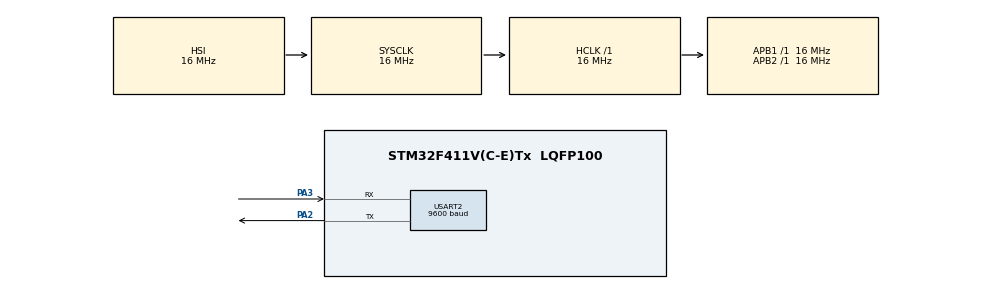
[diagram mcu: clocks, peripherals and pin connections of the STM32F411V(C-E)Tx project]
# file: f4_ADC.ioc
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Mcu.Family=STM32F4
Mcu.Name=STM32F411V(C-E)Tx
Mcu.Package=LQFP100
NVIC.PriorityGroup=NVIC_PRIORITYGROUP_4
PA2.Mode=Asynchronous
PA2.Signal=USART2_TX
PA3.Mode=Asynchronous
PA3.Signal=USART2_RX
ProjectManager.HeapSize=0x200
ProjectManager.StackSize=0x400
ProjectManager.TargetToolchain=STM32CubeIDE
RCC.AHBFreq_Value=16000000
RCC.APB1Freq_Value=16000000
RCC.APB2Freq_Value=16000000
RCC.CortexFreq_Value=16000000
RCC.HSE_VALUE=25000000
RCC.HSI_VALUE=16000000
RCC.LSE_VALUE=32768
RCC.SYSCLKFreq_VALUE=16000000
RCC.VCOOutputFreq_Value=192000000
USART2.BaudRate=9600
USART2.VirtualMode=VM_ASYNC
board=custom

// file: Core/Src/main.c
/* USER CODE BEGIN Header */
/**
  ******************************************************************************
  * @file           : main.c
  * @brief          : Main program body
  ******************************************************************************
  * @attention
  *
  * Copyright (c) 2023 STMicroelectronics.
  * All rights reserved.
  *
  * This software is licensed under terms that can be found in the LICENSE file
  * in the root directory of this software component.
  * If no LICENSE file comes with this software, it is provided AS-IS.
  *
  ******************************************************************************
  */
/* USER CODE END Header */
#include "main.h"

/* USER CODE BEGIN Includes */
#include <string.h>
#include <stdio.h>
#include <stdlib.h>
#include "stm32f4xx.h"
#include "stm32f4xx_hal.h"
/* USER CODE END Includes */

UART_HandleTypeDef huart2;

/* USER CODE BEGIN PV */
uint16_t adc_data;
char mode[6] = "MODE2";
char msg [20];
char msg2 [50];
volatile uint32_t counter = 0;
char systickStr[11];
/* USER CODE END PV */

void SystemClock_Config(void);
static void MX_GPIO_Init(void);
static void MX_USART2_UART_Init(void);

/* USER CODE BEGIN 0 */
void DelayMS(unsigned int time);
void SysTick_Init(uint32_t ticks);
int adc_check (void);
uint16_t adc_rx(void);
void adc_init(void);
void LED_init(void);
void Toggle_all_LEDs(void);
void printTimestamp(void);
void UART2_Init(void);
void UART_Tx(char c);
char UART_Rx(void);
uint16_t read_adc(uint8_t channel);
void Current_Measurement(void);
void Voltage_Measurement(void);
/* USER CODE END 0 */

int main(void)
{

  /* MCU Configuration--------------------------------------------------------*/

  /* Reset of all peripherals, Initializes the Flash interface and the Systick. */
  HAL_Init();

  /* Configure the system clock */
  SystemClock_Config();

  /* USER CODE BEGIN SysInit */
  SysTick_Init(16000);

  /* USER CODE END SysInit */

  /* Initialize all configured peripherals */
  MX_GPIO_Init();
  MX_USART2_UART_Init();
  /* USER CODE BEGIN 2 */
  LED_init();
  adc_init();
  /* USER CODE END 2 */

  /* Infinite loop */
  /* USER CODE BEGIN WHILE */
  while (1)
  {
	  Voltage_Measurement();
	  Current_Measurement();

	  DelayMS(500);
    /* USER CODE END WHILE */

  }
}

void SystemClock_Config(void)
{
  RCC_OscInitTypeDef RCC_OscInitStruct = {0};
  RCC_ClkInitTypeDef RCC_ClkInitStruct = {0};

  /** Configure the main internal regulator output voltage
  */
  __HAL_RCC_PWR_CLK_ENABLE();
  __HAL_PWR_VOLTAGESCALING_CONFIG(PWR_REGULATOR_VOLTAGE_SCALE1);

  /** Initializes the RCC Oscillators according to the specified parameters
  * in the RCC_OscInitTypeDef structure.
  */
  RCC_OscInitStruct.OscillatorType = RCC_OSCILLATORTYPE_HSI;
  RCC_OscInitStruct.HSIState = RCC_HSI_ON;
  RCC_OscInitStruct.HSICalibrationValue = RCC_HSICALIBRATION_DEFAULT;
  RCC_OscInitStruct.PLL.PLLState = RCC_PLL_NONE;
  if (HAL_RCC_OscConfig(&RCC_OscInitStruct) != HAL_OK)
  {
    Error_Handler();
  }

  /** Initializes the CPU, AHB and APB buses clocks
  */
  RCC_ClkInitStruct.ClockType = RCC_CLOCKTYPE_HCLK|RCC_CLOCKTYPE_SYSCLK
                              |RCC_CLOCKTYPE_PCLK1|RCC_CLOCKTYPE_PCLK2;
  RCC_ClkInitStruct.SYSCLKSource = RCC_SYSCLKSOURCE_HSI;
  RCC_ClkInitStruct.AHBCLKDivider = RCC_SYSCLK_DIV1;
  RCC_ClkInitStruct.APB1CLKDivider = RCC_HCLK_DIV1;
  RCC_ClkInitStruct.APB2CLKDivider = RCC_HCLK_DIV1;

  if (HAL_RCC_ClockConfig(&RCC_ClkInitStruct, FLASH_LATENCY_0) != HAL_OK)
  {
    Error_Handler();
  }
}

static void MX_USART2_UART_Init(void)
{

  huart2.Instance = USART2;
  huart2.Init.BaudRate = 9600;
  huart2.Init.WordLength = UART_WORDLENGTH_8B;
  huart2.Init.StopBits = UART_STOPBITS_1;
  huart2.Init.Parity = UART_PARITY_NONE;
  huart2.Init.Mode = UART_MODE_TX_RX;
  huart2.Init.HwFlowCtl = UART_HWCONTROL_NONE;
  huart2.Init.OverSampling = UART_OVERSAMPLING_16;
  if (HAL_UART_Init(&huart2) != HAL_OK)
  {
    Error_Handler();
  }

}

static void MX_GPIO_Init(void)
{

  /* GPIO Ports Clock Enable */
  __HAL_RCC_GPIOA_CLK_ENABLE();

}

/* USER CODE BEGIN 4 */

void Voltage_Measurement(void){
	  adc_data = read_adc(9);
	  // Voltage Measurement 30V
	  float Vin = (adc_data*(2.9)/4095.0);
//			  Vin = Vin*(30.0/2.72); //Correction for Voltage divider
	  Vin += (0.6/30.0)*Vin; //Correction using observation
	  sprintf(msg2, " Vol = %.3f V", Vin);
	  printTimestamp();
	  HAL_UART_Transmit(&huart2, (uint8_t*)(msg2), strlen(msg2), 200);
}

void Current_Measurement(void){

	adc_data = read_adc(8);
	// Current Measurement
	float Vin = (adc_data*(2.9)/4095.0);
	/*Divide Vin by the gain of the apmlifier in this line*/
	float Iin = Vin/(0.0008);
	sprintf(msg2, "Vol = %.3f V, I = %.3f A", Vin, Iin);
	printTimestamp();
	HAL_UART_Transmit(&huart2, (uint8_t*)(msg2), strlen(msg2), 200);
}

uint16_t adc_rx(void){

	uint16_t adcValue = 0;
	adcValue = ADC1->DR;

	return adcValue;
}

uint16_t read_adc(uint8_t channel) {
    // Set the channel in the sequence register
    ADC1->SQR3 = (channel & 0x1F);  // Assuming channel is less than 16

    // Start the conversion
    ADC1->CR2 |= ADC_CR2_SWSTART;  // Start conversion

    // Wait for the end of conversion
    while (!((ADC1->SR & ADC_SR_EOC) == ADC_SR_EOC)) {}

    // Read the converted value
    uint16_t result = ADC1->DR;

    return result;
}

int adc_check (void){
	int check = 0;
	if ((ADC1->SR & ADC_SR_EOC) == ADC_SR_EOC){
		check = 1;
	}
	return check;
}

void Toggle_all_LEDs(void){

	  GPIOD->ODR ^= 0x1000; // Green LED Toggle
	  GPIOD->ODR ^= 0x2000; // Orange LED Toggle
	  GPIOD->ODR ^= 0x4000; // Red LED Toggle
	  GPIOD->ODR ^= 0x8000; // Blue LED Toggle
}

void adc_init(void) {
    // Enable the ADC1 clock
    RCC->APB2ENR |= RCC_APB2ENR_ADC1EN;

    // Enable the GPIOB clock
    RCC->AHB1ENR |= RCC_AHB1ENR_GPIOBEN;

    // Configure PB1 as analog input
    GPIOB->MODER |= GPIO_MODER_MODER1; // Analog mode

    // Configure ADC settings
    ADC1->CR1 &= ~ADC_CR1_RES; // Clear the RES bits for 12-bit resolution
    ADC1->CR2 &= ~ADC_CR2_ALIGN; // Data right-aligned
    ADC1->CR2 |= ADC_CR2_CONT; // Continuous conversion mode
    ADC1->SQR3 &= ~ADC_SQR3_SQ1; // Clear the SQ1 bits
    ADC1->SQR3 |= 9 << ADC_SQR3_SQ1_Pos; // Set the channel number in SQ1 bits (Channel 9 for PB1)
    ADC1->SQR3 |= 8 << ADC_SQR3_SQ1_Pos; // Set the channel number in SQ1 bits (Channel 8 for PB0)
    // Enable the ADC
    ADC1->CR2 |= ADC_CR2_ADON;

    // Wait for ADC to be ready
    DelayMS(100);

    // Start the conversion
    ADC1->CR2 |= ADC_CR2_SWSTART;
}

void DelayMS(unsigned int time){

	for(int i=0; i<=time; i++){
		while ((SysTick->CTRL & 0x00010000) == 0){
				//Wait for 1 millisec.
		}
	}
}

void SysTick_Init(uint32_t ticks){

	SysTick->CTRL = 0; // Disable SysTick

	SysTick->LOAD = ticks-1; // Set Reload Register

	// Setting Interrupt Priority to the highest
	NVIC_SetPriority(SysTick_IRQn, (1<<__NVIC_PRIO_BITS)-1);

	SysTick->VAL = 0; // Reset the SysTick counter value

	SysTick->CTRL |= SysTick_CTRL_CLKSOURCE_Msk; // Selecting internal clock source
	SysTick->CTRL |= SysTick_CTRL_TICKINT_Msk; // Enabling SysTick exception Request when 0

	SysTick->CTRL |= SysTick_CTRL_ENABLE_Msk; // Enable SysTick

}

void LED_init(void){

	RCC->AHB1ENR |= RCC_AHB1ENR_GPIODEN; // Enabling Clock for GPIOD
	GPIOD->MODER |= GPIO_MODER_MODER14_0; //Set bit 0 to 1 Red
	GPIOD->MODER |= GPIO_MODER_MODER15_0; //Set bit 0 to 1 Blue
	GPIOD->MODER |= GPIO_MODER_MODER13_0; //Set bit 0 to 1 Orange
	GPIOD->MODER |= GPIO_MODER_MODER12_0; //Set bit 0 to 1 Green
}

void UART2_Init(void) {
    // Assuming USART2 is used for UART communication
    RCC->APB1ENR |= RCC_APB1ENR_USART2EN;

    // Configure GPIO for UART2 (PA2: TX, PA3: RX)
    RCC->AHB1ENR |= RCC_AHB1ENR_GPIOAEN;
    GPIOA->AFR[0] |= 0x0700; // AF7 for USART2 on PA2 (TX)
    GPIOA->AFR[0] |= 0x0070; // AF7 for USART2 on PA3 (RX)
    GPIOA->MODER |= GPIO_MODER_MODER2_1 | GPIO_MODER_MODER3_1; // Alternate function mode for PA2 (TX) and PA3 (RX)

    // Configure USART2
    USART2->BRR = 0x0683; // 9600 baud rate @ 16MHz (adjust as needed)
    USART2->CR1 |= USART_CR1_UE | USART_CR1_TE | USART_CR1_RE; // Enable USART2, transmitter, and receiver
}

void SysTick_Handler(void) {

	if (counter == 0xffffffff) {
        counter = 0; // Reset the counter if the maximum value is reached
    } else {
        counter++; // Increment the counter
    }
}

void printTimestamp(void) {
	sprintf(msg, "   Time = %lu ms:", counter);
	HAL_UART_Transmit(&huart2, (uint8_t*)(msg), strlen(msg), 200);
}

void UART_Tx(char c){

	while ((USART1->SR & USART_SR_TXE) != USART_SR_TXE){
		__NOP();
	}
	USART1->DR = c;
}

char UART_Rx(void){

	char c;

	while ((USART1->SR & USART_SR_RXNE) != USART_SR_RXNE){
		__NOP();
	}
	c = USART1->DR;

	return c;
}

/* USER CODE END 4 */

void Error_Handler(void)
{
  __disable_irq();
  while (1)
  {
  }
}
